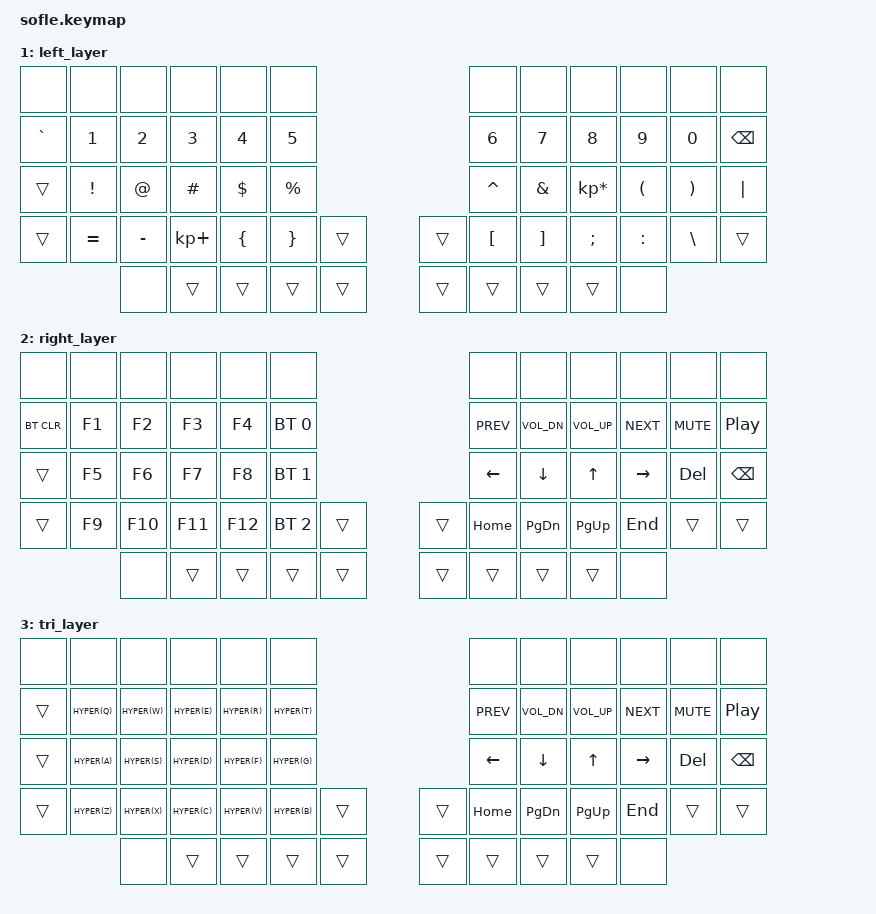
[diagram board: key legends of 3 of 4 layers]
// Copyright (c) 2020 The ZMK Contributors
// SPDX-License-Identifier: MIT
#include <behaviors.dtsi>
#include <dt-bindings/zmk/keys.h>
#include <dt-bindings/zmk/bt.h>

// Layer aliases
#define LEF 1
#define RIG 2
#define TRI 3

// Home row mods macro
#define HRML(k2,k3,k4) &hrm LCTRL k2 &hrm LALT k3  &hrm LGUI k4
#define HRMR(k1,k2,k3) &hrm RGUI k1  &hrm RALT k2  &hrm RCTRL k3

#define HYPER(k) &kp LS(LC(LA(LG(k))))

// NOTE: I'm slowly removing keys from the Sofle PCB since I want to try to find an optimal layout (for me) before designing/buying new hardware.
//       If you see empty keys, that's the reason.
//
// Legend: Mod-Tap: <Hold>@<Tap>
/ {
    behaviors {
        hrm: hold_tap {
            label = "hold_tap";
            compatible = "zmk,behavior-hold-tap";
            #binding-cells = <2>;
            flavor = "tap-preferred";
            tapping-term-ms = <220>;
            quick-tap-ms = <150>;
            global-quick-tap;
            bindings = <&kp>, <&kp>;
        };
    };

    conditional_layers {
        compatible = "zmk,conditional-layers";
        tri_layer {
            if-layers = <RIG LEF>;
            then-layer = <TRI>;
        };
    };

    keymap {
        compatible = "zmk,keymap";

        default_layer {
            bindings = <
                // ╭────────────┬────────────┬────────────┬────────────┬────────────┬────────────╮                             ╭────────────┬────────────┬────────────┬────────────┬────────────┬────────────╮
                // |            |            |            |            |            |            |                             |            |            |            |            |            |            |
                       &none        &none        &none        &none        &none        &none                                      &none        &none        &none        &none        &none        &none
                // ├────────────┼────────────┼────────────┼────────────┼────────────┼────────────┤                             ├────────────┼────────────┼────────────┼────────────┼────────────┼────────────┤
                // |  TAB       |  Q         |  W         |  E         |  R         |  T         |                             |  Y         |  U         |  I         |  O         |   P        |      ⌫     |
                     &kp TAB      &kp Q        &kp W        &kp E        &kp R        &kp T                                      &kp Y        &kp U        &kp I        &kp O        &kp P        &kp BSPC
                // ├────────────┼────────────┼────────────┼────────────┼────────────┼────────────┤                             ├────────────┼────────────┼────────────┼────────────┼────────────┼────────────┤
                // |  CTRL@ESC  |  A         |  S         |  D         |  F         |  G         |                             |  H         |  J         |  K         |  L         |   ;        |   '        |
                     &mt LCTRL ESC &kp A       HRML(S,          D,          F)          &kp G                                      &kp H      HRMR(J,          K,           L)        &kp SEMI     &kp SQT
                // ├────────────┼────────────┼────────────┼────────────┼────────────┼────────────┼────────────╮   ╭────────────┼────────────┼────────────┼────────────┼────────────┼────────────┼────────────┤
                // | SHIFT      |  Z         |  X         |  C         |  V         |  B         |            |   |            |  N         |  M         |  ,         |  .         |   /        | SHIFT      |
                     &kp LSHFT    &kp Z        &kp X        &kp C        &kp V        &kp B        &none            &none        &kp N        &kp M        &kp COMMA    &kp DOT      &kp FSLH     &kp RSHFT
                // ╰────────────┴────────────┼────────────┼────────────┼────────────┼────────────┼────────────┤   ├────────────┼────────────┼────────────┼────────────┼────────────┼────────────┴────────────╯
                //                           |            |      ⌥     |      ⌘     |     LEF    |  ENTER     |   | SPACE      |    RIG     |     ⌘      |     ⌥      |            |
                                                 &none        &kp LALT   &kp LGUI     &mo LEF       &kp RET          &kp SPACE    &mo RIG      &kp RGUI     &kp RALT       &none
                //                           ╰────────────┴────────────┴────────────┴────────────┴────────────╯   ╰────────────┴────────────┴────────────┴────────────┴────────────╯
            >;

            sensor-bindings = <&inc_dec_kp C_VOL_UP C_VOL_DN &inc_dec_kp PG_UP PG_DN>;
        };

        left_layer {
            bindings = <
                // ╭────────────┬────────────┬────────────┬────────────┬────────────┬────────────╮                             ╭────────────┬────────────┬────────────┬────────────┬────────────┬────────────╮
                // |            |            |            |            |            |            |                             |            |            |            |            |            |            |
                       &none        &none        &none        &none        &none        &none                                      &none        &none        &none        &none        &none        &none
                // ├────────────┼────────────┼────────────┼────────────┼────────────┼────────────┤                             ├────────────┼────────────┼────────────┼────────────┼────────────┼────────────┤
                // |     `      |     1      |     2      |     3      |     4      |     5      |                             |     6      |     7      |     8      |     9      |     0      |      ⌫     |
                     &kp GRAVE      &kp N1      &kp N2        &kp N3      &kp N4        &kp N5                                     &kp N6       &kp N7       &kp N8       &kp N9       &kp N0      &kp BSPC
                // ├────────────┼────────────┼────────────┼────────────┼────────────┼────────────┤                             ├────────────┼────────────┼────────────┼────────────┼────────────┼────────────┤
                // |            |    !       |  @         |  #         |  $         |  %         |                             |  %         |  &         |  *         |  (         |   )        |   |        |
                     &trans       &kp EXCL     &kp AT       &kp HASH     &kp DLLR     &kp PRCNT                                  &kp CARET     &kp AMPS  &kp KP_MULTIPLY &kp LPAR     &kp RPAR    &kp PIPE
                // ├────────────┼────────────┼────────────┼────────────┼────────────┼────────────┼────────────╮   ╭────────────┼────────────┼────────────┼────────────┼────────────┼────────────┼────────────┤
                // |            |     =      |     -      |     +      |     {      |     }      |            |   |            |     [      |     ]      |     ;      |     :      |      \     |            |
                     &trans        &kp EQUAL    &kp MINUS  &kp KP_PLUS    &kp LBRC     &kp RBRC     &trans           &trans       &kp LBKT     &kp RBKT     &kp SEMI    &kp COLON     &kp BSLH     &trans
                // ╰────────────┴────────────┼────────────┼────────────┼────────────┼────────────┼────────────┤   ├────────────┼────────────┼────────────┼────────────┼────────────┼────────────┴────────────╯
                //                           |            |            |            |            |            |   |            |            |            |            |            |
                                                 &none        &trans     &trans       &trans       &trans           &trans       &trans       &trans       &trans         &none
                //                           ╰────────────┴────────────┴────────────┴────────────┴────────────╯   ╰────────────┴────────────┴────────────┴────────────┴────────────╯
            >;

            sensor-bindings = <&inc_dec_kp C_VOL_UP C_VOL_DN &inc_dec_kp PG_UP PG_DN>;
        };

        right_layer {
            bindings = <
                // ╭────────────┬────────────┬────────────┬────────────┬────────────┬────────────╮                             ╭────────────┬────────────┬────────────┬────────────┬────────────┬────────────╮
                // |            |            |            |            |            |            |                             |            |            |            |            |            |            |
                       &none        &none        &none        &none        &none        &none                                      &none        &none        &none        &none        &none        &none
                // ├────────────┼────────────┼────────────┼────────────┼────────────┼────────────┤                             ├────────────┼────────────┼────────────┼────────────┼────────────┼────────────┤
                // |  BT CLEAR  |     F1     |    F2      |    F3      |    F4      |    BT0     |                             | PREV SONG  |  VOL DOWN  |   VOL UP   | NEXT SONG  |    MUTE    | PLAY/PAUSE |
                     &bt BT_CLR    &kp F1      &kp F2        &kp F3      &kp F4      &bt BT_SEL 0                                &kp C_PREV  &kp C_VOL_DN &kp C_VOL_UP  &kp C_NEXT  &kp C_MUTE     &kp C_PP
                // ├────────────┼────────────┼────────────┼────────────┼────────────┼────────────┤                             ├────────────┼────────────┼────────────┼────────────┼────────────┼────────────┤
                // |            |     F5     |    F6      |    F7      |    F8      |    BT1     |                             |     ←      |      ↓     |      ↑     |      →     |      ⌦     |      ⌫     |
                       &trans     &kp F5       &kp F6       &kp F7       &kp F8      &bt BT_SEL 1                                 &kp LEFT     &kp DOWN      &kp UP      &kp RIGHT     &kp DEL    &kp BSPC
                // ├────────────┼────────────┼────────────┼────────────┼────────────┼────────────┼────────────╮   ╭────────────┼────────────┼────────────┼────────────┼────────────┼────────────┼────────────┤
                // |            |     F9     |    F10     |    F11     |    F12     |    BT2     |            |   |            |    HOME    |   PGDOWN   |    PGUP    |    END     |            |            |
                       &trans       &kp F9       &kp F10    &kp F11        &kp F12   &bt BT_SEL 2    &trans           &trans       &kp HOME     &kp PG_DN    &kp PG_UP     &kp END      &trans       &trans
                // ╰────────────┴────────────┼────────────┼────────────┼────────────┼────────────┼────────────┤   ├────────────┼────────────┼────────────┼────────────┼────────────┼────────────┴────────────╯
                //                           |            |            |            |            |            |   |            |            |            |            |            |
                                                 &none        &trans     &trans       &trans       &trans           &trans       &trans       &trans       &trans         &none
                //                           ╰────────────┴────────────┴────────────┴────────────┴────────────╯   ╰────────────┴────────────┴────────────┴────────────┴────────────╯
            >;

            sensor-bindings = <&inc_dec_kp C_VOL_UP C_VOL_DN &inc_dec_kp PG_UP PG_DN>;
        };

        // TODO: I want this to be my launch layer (and maybe more)
        tri_layer {
            bindings = <
                // ╭────────────┬────────────┬────────────┬────────────┬────────────┬────────────╮                             ╭────────────┬────────────┬────────────┬────────────┬────────────┬────────────╮
                // |            |            |            |            |            |            |                             |            |            |            |            |            |            |
                       &none        &none        &none        &none        &none        &none                                      &none        &none        &none        &none        &none        &none
                // ├────────────┼────────────┼────────────┼────────────┼────────────┼────────────┤                             ├────────────┼────────────┼────────────┼────────────┼────────────┼────────────┤
                // |            |  HYPER Q   |  HYPER Q   |  HYPER E   |  HYPER R   |  HYPER T   |                             | PREV SONG  |  VOL DOWN  |   VOL UP   | NEXT SONG  |    MUTE    | PLAY/PAUSE |
                        &trans     HYPER(Q)     HYPER(W)     HYPER(E)     HYPER(R)     HYPER(T)                                  &kp C_PREV  &kp C_VOL_DN &kp C_VOL_UP  &kp C_NEXT  &kp C_MUTE     &kp C_PP
                // ├────────────┼────────────┼────────────┼────────────┼────────────┼────────────┤                             ├────────────┼────────────┼────────────┼────────────┼────────────┼────────────┤
                // |            |  HYPER A   |  HYPER S   |  HYPER D   |  HYPER F   |  HYPER G   |                             |     ←      |      ↓     |      ↑     |      →     |      ⌦     |      ⌫     |
                        &trans     HYPER(A)     HYPER(S)     HYPER(D)     HYPER(F)     HYPER(G)                                  &kp LEFT     &kp DOWN      &kp UP      &kp RIGHT     &kp DEL    &kp BSPC
                // ├────────────┼────────────┼────────────┼────────────┼────────────┼────────────┼────────────╮   ╭────────────┼────────────┼────────────┼────────────┼────────────┼────────────┼────────────┤
                // |            |  HYPER Z   |  HYPER X   |  HYPER C   |  HYPER V   |  HYPER B   |            |   |            |    HOME    |   PGDOWN   |    PGUP    |    END     |            |            |
                        &trans     HYPER(Z)     HYPER(X)     HYPER(C)     HYPER(V)     HYPER(B)     &trans           &trans       &kp HOME     &kp PG_DN    &kp PG_UP     &kp END      &trans       &trans
                // ╰────────────┴────────────┼────────────┼────────────┼────────────┼────────────┼────────────┤   ├────────────┼────────────┼────────────┼────────────┼────────────┼────────────┴────────────╯
                //                           |            |            |            |            |            |   |            |            |            |            |            |
                                                 &none        &trans     &trans       &trans       &trans           &trans       &trans       &trans       &trans         &none
                //                           ╰────────────┴────────────┴────────────┴────────────┴────────────╯   ╰────────────┴────────────┴────────────┴────────────┴────────────╯
            >;

            sensor-bindings = <&inc_dec_kp C_VOL_UP C_VOL_DN &inc_dec_kp PG_UP PG_DN>;
        };
    };
};
